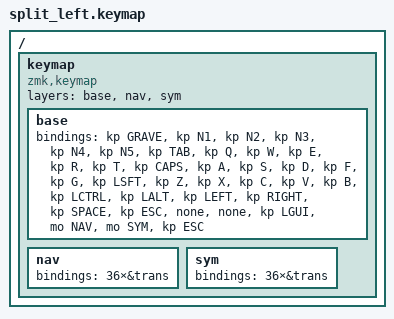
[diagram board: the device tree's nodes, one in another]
#include <dt-bindings/zmk/bt.h>
/ {
  keymap {
    compatible = "zmk,keymap";
    layers = <&base &nav &sym>;

    base {
      bindings = <
        /* R0 */ &kp GRAVE  &kp N1  &kp N2  &kp N3  &kp N4  &kp N5
        /* R1 */ &kp TAB    &kp Q   &kp W   &kp E   &kp R   &kp T
        /* R2 */ &kp CAPS   &kp A   &kp S   &kp D   &kp F   &kp G
        /* R3 */ &kp LSFT   &kp Z   &kp X   &kp C   &kp V   &kp B
        /* R4 */ &kp LCTRL  &kp LALT &kp LEFT &kp RIGHT &kp SPACE &kp ESC
        /* R5 */ &none      &none   &kp LGUI &mo NAV  &mo SYM  &kp ESC
      >;
    };
    nav { bindings = < 36×&trans >; };
    sym { bindings = < 36×&trans >; };
  };
};
